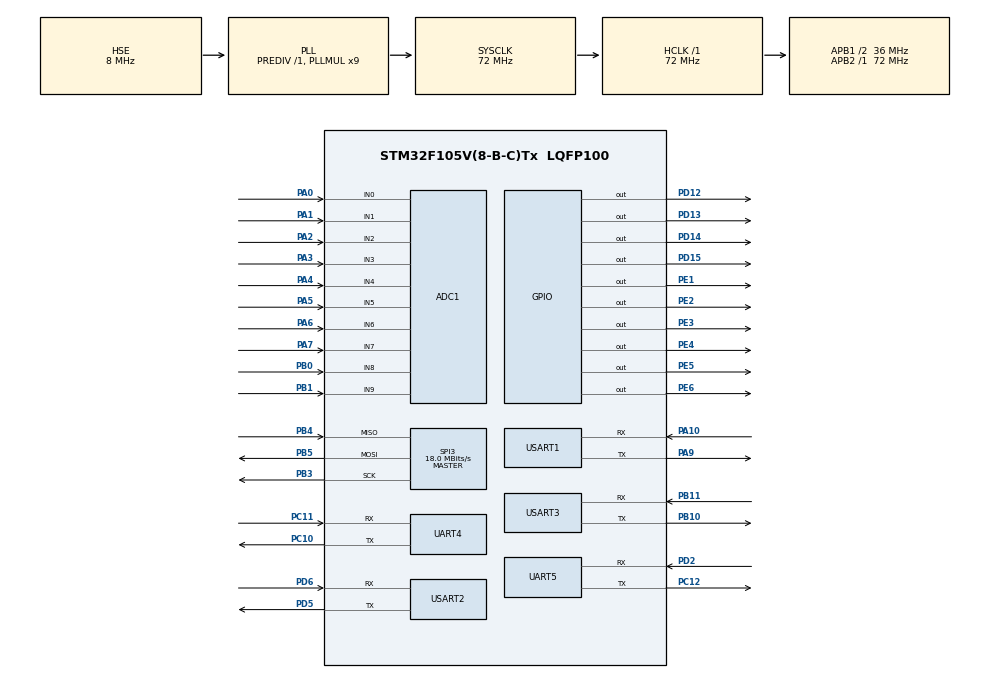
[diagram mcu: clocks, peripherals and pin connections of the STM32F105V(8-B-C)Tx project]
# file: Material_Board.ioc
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ADC1.Channel-10\#ChannelRegularConversion=ADC_CHANNEL_5
ADC1.Channel-11\#ChannelRegularConversion=ADC_CHANNEL_6
ADC1.Channel-12\#ChannelRegularConversion=ADC_CHANNEL_7
ADC1.Channel-13\#ChannelRegularConversion=ADC_CHANNEL_8
ADC1.Channel-14\#ChannelRegularConversion=ADC_CHANNEL_9
ADC1.Channel-5\#ChannelRegularConversion=ADC_CHANNEL_0
ADC1.Channel-6\#ChannelRegularConversion=ADC_CHANNEL_1
ADC1.Channel-7\#ChannelRegularConversion=ADC_CHANNEL_2
ADC1.Channel-8\#ChannelRegularConversion=ADC_CHANNEL_3
ADC1.Channel-9\#ChannelRegularConversion=ADC_CHANNEL_4
ADC1.ContinuousConvMode=ENABLE
ADC1.NbrOfConversion=10
ADC1.NbrOfConversionFlag=1
ADC1.Rank-10\#ChannelRegularConversion=6
ADC1.Rank-11\#ChannelRegularConversion=7
ADC1.Rank-12\#ChannelRegularConversion=8
ADC1.Rank-13\#ChannelRegularConversion=9
ADC1.Rank-14\#ChannelRegularConversion=10
ADC1.Rank-5\#ChannelRegularConversion=1
ADC1.Rank-6\#ChannelRegularConversion=2
ADC1.Rank-7\#ChannelRegularConversion=3
ADC1.Rank-8\#ChannelRegularConversion=4
ADC1.Rank-9\#ChannelRegularConversion=5
ADC1.SamplingTime-10\#ChannelRegularConversion=ADC_SAMPLETIME_239CYCLES_5
ADC1.SamplingTime-11\#ChannelRegularConversion=ADC_SAMPLETIME_239CYCLES_5
ADC1.SamplingTime-12\#ChannelRegularConversion=ADC_SAMPLETIME_239CYCLES_5
ADC1.SamplingTime-13\#ChannelRegularConversion=ADC_SAMPLETIME_239CYCLES_5
ADC1.SamplingTime-14\#ChannelRegularConversion=ADC_SAMPLETIME_239CYCLES_5
ADC1.SamplingTime-5\#ChannelRegularConversion=ADC_SAMPLETIME_239CYCLES_5
ADC1.SamplingTime-6\#ChannelRegularConversion=ADC_SAMPLETIME_239CYCLES_5
ADC1.SamplingTime-7\#ChannelRegularConversion=ADC_SAMPLETIME_239CYCLES_5
ADC1.SamplingTime-8\#ChannelRegularConversion=ADC_SAMPLETIME_239CYCLES_5
ADC1.SamplingTime-9\#ChannelRegularConversion=ADC_SAMPLETIME_239CYCLES_5
ADC1.master=1
Dma.ADC1.0.Direction=DMA_PERIPH_TO_MEMORY
Dma.ADC1.0.Instance=DMA1_Channel1
Dma.ADC1.0.MemDataAlignment=DMA_MDATAALIGN_HALFWORD
Dma.ADC1.0.MemInc=DMA_MINC_ENABLE
Dma.ADC1.0.Mode=DMA_NORMAL
Dma.ADC1.0.PeriphDataAlignment=DMA_PDATAALIGN_HALFWORD
Dma.ADC1.0.PeriphInc=DMA_PINC_DISABLE
Dma.ADC1.0.Priority=DMA_PRIORITY_LOW
Dma.Request0=ADC1
Mcu.Family=STM32F1
Mcu.Name=STM32F105V(8-B-C)Tx
Mcu.Package=LQFP100
NVIC.DMA1_Channel1_IRQn=true\:0\:0\:false\:false\:true\:false\:true\:true
NVIC.PriorityGroup=NVIC_PRIORITYGROUP_4
OSC_IN.Mode=HSE-External-Oscillator
OSC_IN.Signal=RCC_OSC_IN
OSC_OUT.Mode=HSE-External-Oscillator
OSC_OUT.Signal=RCC_OSC_OUT
PA0-WKUP.Signal=ADCx_IN0
PA1.Signal=ADCx_IN1
PA10.Mode=Asynchronous
PA10.Signal=USART1_RX
PA2.Signal=ADCx_IN2
PA3.Signal=ADCx_IN3
PA4.Signal=ADCx_IN4
PA5.Signal=ADCx_IN5
PA6.Signal=ADCx_IN6
PA7.Signal=ADCx_IN7
PA9.Mode=Asynchronous
PA9.Signal=USART1_TX
PB0.Signal=ADCx_IN8
PB1.Signal=ADCx_IN9
PB10.Mode=Asynchronous
PB10.Signal=USART3_TX
PB11.Mode=Asynchronous
PB11.Signal=USART3_RX
PB3.Mode=Full_Duplex_Master
PB3.Signal=SPI3_SCK
PB4.Mode=Full_Duplex_Master
PB4.Signal=SPI3_MISO
PB5.Mode=Full_Duplex_Master
PB5.Signal=SPI3_MOSI
PC10.Mode=Asynchronous
PC10.Signal=UART4_TX
PC11.Mode=Asynchronous
PC11.Signal=UART4_RX
PC12.Mode=Asynchronous
PC12.Signal=UART5_TX
PD12.GPIO_ModeDefaultOutputPP=GPIO_MODE_OUTPUT_PP
PD12.GPIO_PuPd=GPIO_NOPULL
PD12.GPIO_Speed=GPIO_SPEED_FREQ_LOW
PD12.PinState=GPIO_PIN_RESET
PD12.Signal=GPIO_Output
PD13.GPIO_ModeDefaultOutputPP=GPIO_MODE_OUTPUT_PP
PD13.GPIO_PuPd=GPIO_NOPULL
PD13.GPIO_Speed=GPIO_SPEED_FREQ_LOW
PD13.PinState=GPIO_PIN_RESET
PD13.Signal=GPIO_Output
PD14.GPIO_ModeDefaultOutputPP=GPIO_MODE_OUTPUT_PP
PD14.GPIO_PuPd=GPIO_NOPULL
PD14.GPIO_Speed=GPIO_SPEED_FREQ_LOW
PD14.PinState=GPIO_PIN_RESET
PD14.Signal=GPIO_Output
PD15.GPIO_ModeDefaultOutputPP=GPIO_MODE_OUTPUT_PP
PD15.GPIO_PuPd=GPIO_NOPULL
PD15.GPIO_Speed=GPIO_SPEED_FREQ_LOW
PD15.PinState=GPIO_PIN_RESET
PD15.Signal=GPIO_Output
PD2.Mode=Asynchronous
PD2.Signal=UART5_RX
PD5.Mode=Asynchronous
PD5.Signal=USART2_TX
PD6.Mode=Asynchronous
PD6.Signal=USART2_RX
PE1.GPIO_ModeDefaultOutputPP=GPIO_MODE_OUTPUT_PP
PE1.GPIO_PuPd=GPIO_NOPULL
PE1.GPIO_Speed=GPIO_SPEED_FREQ_LOW
PE1.PinState=GPIO_PIN_RESET
PE1.Signal=GPIO_Output
PE2.GPIO_ModeDefaultOutputPP=GPIO_MODE_OUTPUT_PP
PE2.GPIO_PuPd=GPIO_NOPULL
PE2.GPIO_Speed=GPIO_SPEED_FREQ_LOW
PE2.PinState=GPIO_PIN_RESET
PE2.Signal=GPIO_Output
PE3.GPIO_ModeDefaultOutputPP=GPIO_MODE_OUTPUT_PP
PE3.GPIO_PuPd=GPIO_NOPULL
PE3.GPIO_Speed=GPIO_SPEED_FREQ_LOW
PE3.PinState=GPIO_PIN_RESET
PE3.Signal=GPIO_Output
PE4.GPIO_ModeDefaultOutputPP=GPIO_MODE_OUTPUT_PP
PE4.GPIO_PuPd=GPIO_NOPULL
PE4.GPIO_Speed=GPIO_SPEED_FREQ_LOW
PE4.PinState=GPIO_PIN_RESET
PE4.Signal=GPIO_Output
PE5.GPIO_ModeDefaultOutputPP=GPIO_MODE_OUTPUT_PP
PE5.GPIO_PuPd=GPIO_NOPULL
PE5.GPIO_Speed=GPIO_SPEED_FREQ_LOW
PE5.PinState=GPIO_PIN_RESET
PE5.Signal=GPIO_Output
PE6.GPIO_ModeDefaultOutputPP=GPIO_MODE_OUTPUT_PP
PE6.GPIO_PuPd=GPIO_NOPULL
PE6.GPIO_Speed=GPIO_SPEED_FREQ_LOW
PE6.PinState=GPIO_PIN_RESET
PE6.Signal=GPIO_Output
ProjectManager.HeapSize=0x200
ProjectManager.StackSize=0x400
ProjectManager.TargetToolchain=MDK-ARM V5.32
RCC.ADCPresc=RCC_ADCPCLK2_DIV6
RCC.AHBFreq_Value=72000000
RCC.APB1CLKDivider=RCC_HCLK_DIV2
RCC.APB1Freq_Value=36000000
RCC.APB1TimFreq_Value=72000000
RCC.APB2Freq_Value=72000000
RCC.APB2TimFreq_Value=72000000
RCC.EnbaleCSS=true
RCC.HCLKFreq_Value=72000000
RCC.PLLMUL=RCC_PLL_MUL9
RCC.PLLSourceVirtual=RCC_PLLSOURCE_HSE
RCC.SYSCLKFreq_VALUE=72000000
RCC.SYSCLKSource=RCC_SYSCLKSOURCE_PLLCLK
RCC.USBFreq_Value=48000000
SH.ADCx_IN0.0=ADC1_IN0,IN0
SH.ADCx_IN1.0=ADC1_IN1,IN1
SH.ADCx_IN2.0=ADC1_IN2,IN2
SH.ADCx_IN3.0=ADC1_IN3,IN3
SH.ADCx_IN4.0=ADC1_IN4,IN4
SH.ADCx_IN5.0=ADC1_IN5,IN5
SH.ADCx_IN6.0=ADC1_IN6,IN6
SH.ADCx_IN7.0=ADC1_IN7,IN7
SH.ADCx_IN8.0=ADC1_IN8,IN8
SH.ADCx_IN9.0=ADC1_IN9,IN9
SPI3.CalculateBaudRate=18.0 MBits/s
SPI3.Direction=SPI_DIRECTION_2LINES
SPI3.Mode=SPI_MODE_MASTER
SPI3.VirtualType=VM_MASTER
UART4.VirtualMode=Asynchronous
UART5.VirtualMode=Asynchronous
USART1.VirtualMode=VM_ASYNC
USART2.VirtualMode=VM_ASYNC
USART3.VirtualMode=VM_ASYNC
VP_SYS_VS_ND.Mode=No_Debug
board=custom

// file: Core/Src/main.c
/* USER CODE BEGIN Header */
/**
  ******************************************************************************
  * @file           : main.c
  * @brief          : Main program body
  ******************************************************************************
  * @attention
  *
  * Copyright (c) 2022 STMicroelectronics.
  * All rights reserved.
  *
  * This software is licensed under terms that can be found in the LICENSE file
  * in the root directory of this software component.
  * If no LICENSE file comes with this software, it is provided AS-IS.
  *
  ******************************************************************************
  */
/* USER CODE END Header */
#include "main.h"
#include "adc.h"
#include "dma.h"
#include "spi.h"
#include "usart.h"
#include "gpio.h"

/* USER CODE BEGIN Includes */
#include "includes.h"
/* USER CODE END Includes */

void SystemClock_Config(void);

int main(void)
{

  /* MCU Configuration--------------------------------------------------------*/

  /* Reset of all peripherals, Initializes the Flash interface and the Systick. */
  HAL_Init();

  /* Configure the system clock */
  SystemClock_Config();

  /* Initialize all configured peripherals */
  MX_GPIO_Init();
  MX_DMA_Init();
  MX_ADC1_Init();
  MX_USART3_UART_Init();
  MX_SPI3_Init();
  MX_UART4_Init();
  MX_UART5_Init();
  MX_USART1_UART_Init();
  MX_USART2_UART_Init();

  /* Infinite loop */
  while (1)
  {

  }
}

void SystemClock_Config(void)
{
  RCC_OscInitTypeDef RCC_OscInitStruct = {0};
  RCC_ClkInitTypeDef RCC_ClkInitStruct = {0};
  RCC_PeriphCLKInitTypeDef PeriphClkInit = {0};

  /** Initializes the RCC Oscillators according to the specified parameters
  * in the RCC_OscInitTypeDef structure.
  */
  RCC_OscInitStruct.OscillatorType = RCC_OSCILLATORTYPE_HSE;
  RCC_OscInitStruct.HSEState = RCC_HSE_ON;
  RCC_OscInitStruct.HSEPredivValue = RCC_HSE_PREDIV_DIV1;
  RCC_OscInitStruct.HSIState = RCC_HSI_ON;
  RCC_OscInitStruct.Prediv1Source = RCC_PREDIV1_SOURCE_HSE;
  RCC_OscInitStruct.PLL.PLLState = RCC_PLL_ON;
  RCC_OscInitStruct.PLL.PLLSource = RCC_PLLSOURCE_HSE;
  RCC_OscInitStruct.PLL.PLLMUL = RCC_PLL_MUL9;
  RCC_OscInitStruct.PLL2.PLL2State = RCC_PLL_NONE;
  if (HAL_RCC_OscConfig(&RCC_OscInitStruct) != HAL_OK)
  {
    Error_Handler();
  }

  /** Initializes the CPU, AHB and APB buses clocks
  */
  RCC_ClkInitStruct.ClockType = RCC_CLOCKTYPE_HCLK|RCC_CLOCKTYPE_SYSCLK
                              |RCC_CLOCKTYPE_PCLK1|RCC_CLOCKTYPE_PCLK2;
  RCC_ClkInitStruct.SYSCLKSource = RCC_SYSCLKSOURCE_PLLCLK;
  RCC_ClkInitStruct.AHBCLKDivider = RCC_SYSCLK_DIV1;
  RCC_ClkInitStruct.APB1CLKDivider = RCC_HCLK_DIV2;
  RCC_ClkInitStruct.APB2CLKDivider = RCC_HCLK_DIV1;

  if (HAL_RCC_ClockConfig(&RCC_ClkInitStruct, FLASH_LATENCY_2) != HAL_OK)
  {
    Error_Handler();
  }
  PeriphClkInit.PeriphClockSelection = RCC_PERIPHCLK_ADC;
  PeriphClkInit.AdcClockSelection = RCC_ADCPCLK2_DIV6;
  if (HAL_RCCEx_PeriphCLKConfig(&PeriphClkInit) != HAL_OK)
  {
    Error_Handler();
  }

  /** Enables the Clock Security System
  */
  HAL_RCC_EnableCSS();

  /** Configure the Systick interrupt time
  */
  __HAL_RCC_PLLI2S_ENABLE();
}

void Error_Handler(void)
{
  __disable_irq();
  while (1)
  {
  }
}
